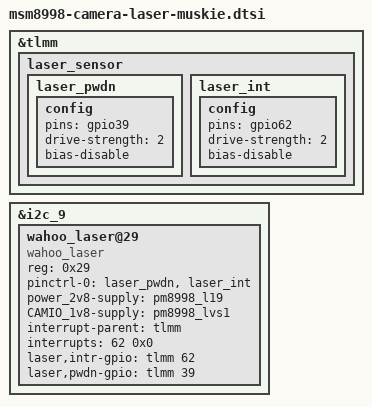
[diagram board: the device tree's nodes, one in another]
/*
 * Copyright (c) 2015, The Linux Foundation. All rights reserved.
 *
 * This program is free software; you can redistribute it and/or modify
 * it under the terms of the GNU General Public License version 2 and
 * only version 2 as published by the Free Software Foundation.
 *
 * This program is distributed in the hope that it will be useful,
 * but WITHOUT ANY WARRANTY; without even the implied warranty of
 * MERCHANTABILITY or FITNESS FOR A PARTICULAR PURPOSE.  See the
 * GNU General Public License for more details.
 */

&tlmm {
	laser_sensor {
        	laser_pwdn:laser_pwdn {
                	config {
                          	pins = "gpio39";
	                        drive-strength = <2>;
        	                bias-disable;
                	};
	        };
	        laser_int:laser_int {
	                config {
        	                pins = "gpio62";
                	        drive-strength = <2>;
                        	bias-disable;
	                };
        	};
	};
};

&i2c_9 {
	wahoo_laser@29 {
		compatible = "wahoo_laser";
		reg = <0x29>;
		pinctrl-names = "laser_gpio_init";
		pinctrl-0 = <&laser_pwdn &laser_int>;
		power_2v8-supply = <&pm8998_l19>;
		CAMIO_1v8-supply = <&pm8998_lvs1>;
		interrupt-parent = <&tlmm>;
		interrupts = <62 0x0>;
		laser,intr-gpio = <&tlmm 62 0>;
		laser,pwdn-gpio = <&tlmm 39 0>;
	};
};

